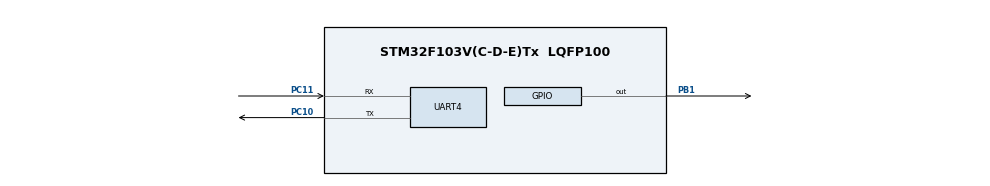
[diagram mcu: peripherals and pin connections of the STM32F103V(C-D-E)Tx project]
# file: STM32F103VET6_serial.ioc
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Mcu.Family=STM32F1
Mcu.Name=STM32F103V(C-D-E)Tx
Mcu.Package=LQFP100
NVIC.PriorityGroup=NVIC_PRIORITYGROUP_4
PB1.Signal=GPIO_Output
PC10.Mode=Asynchronous
PC10.Signal=UART4_TX
PC11.Mode=Asynchronous
PC11.Signal=UART4_RX
ProjectManager.HeapSize=0x200
ProjectManager.StackSize=0x400
ProjectManager.TargetToolchain=Makefile
RCC.APB1Freq_Value=8000000
RCC.APB2Freq_Value=8000000
UART4.VirtualMode=Asynchronous
VP_SYS_VS_ND.Mode=No_Debug
board=custom

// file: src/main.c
/* USER CODE BEGIN Header */
/**
******************************************************************************
* @file           : main.c
* @brief          : Main program body
******************************************************************************
* @attention
*
* <h2><center>&copy; Copyright (c) 2019 STMicroelectronics.
* All rights reserved.</center></h2>
*
* This software component is licensed by ST under BSD 3-Clause license,
* the "License"; You may not use this file except in compliance with the
* License. You may obtain a copy of the License at:
*                        opensource.org/licenses/BSD-3-Clause
*
******************************************************************************
*/
/* USER CODE END Header */

#include "main.h"
#include "uart.h"

UART_HandleTypeDef huart4;
uint8_t gSystemInitialized = 0;
uint8_t led = 0;

void SystemClock_Config(void);
static void MX_GPIO_Init(void);
static void MX_UART4_Init(void);

/* USER CODE BEGIN 0 */
void main_tick_1ms()   {
}
void main_tick_5ms()   {}
void main_tick_10ms()  {}
void main_tick_50ms()  {
    led = 1 - led;
    HAL_GPIO_WritePin(GPIOB, GPIO_PIN_1,led);
}
void main_tick_100ms() {}
void main_tick_500ms() {}
void main_tick_1s()    {
    /* while (!(UART4->SR & USART_SR_TXE)); */
    /* UART4->DR = 'a'; */
}
/* USER CODE END 0 */

int main(void)
{

    /* MCU Configuration--------------------------------------------------------*/

    /* Reset of all peripherals, Initializes the Flash interface and the Systick. */
    HAL_Init();

    /* Configure the system clock */
    SystemClock_Config();

    /* Initialize all configured peripherals */
    MX_GPIO_Init();
    MX_UART4_Init();
    /* USER CODE BEGIN 2 */
    gSystemInitialized=1;
    /* USER CODE END 2 */

    /* Infinite loop */
    while (1)
    {

    }
}

void SystemClock_Config(void)
{
    RCC_OscInitTypeDef RCC_OscInitStruct = {0};
    RCC_ClkInitTypeDef RCC_ClkInitStruct = {0};

    /** Initializes the CPU, AHB and APB busses clocks
     */
    RCC_OscInitStruct.OscillatorType = RCC_OSCILLATORTYPE_HSI;
    RCC_OscInitStruct.HSIState = RCC_HSI_ON;
    RCC_OscInitStruct.HSICalibrationValue = RCC_HSICALIBRATION_DEFAULT;
    RCC_OscInitStruct.PLL.PLLState = RCC_PLL_NONE;
    if (HAL_RCC_OscConfig(&RCC_OscInitStruct) != HAL_OK)
    {
        Error_Handler();
    }
    /** Initializes the CPU, AHB and APB busses clocks
     */
    RCC_ClkInitStruct.ClockType = RCC_CLOCKTYPE_HCLK|RCC_CLOCKTYPE_SYSCLK
        |RCC_CLOCKTYPE_PCLK1|RCC_CLOCKTYPE_PCLK2;
    RCC_ClkInitStruct.SYSCLKSource = RCC_SYSCLKSOURCE_HSI;
    RCC_ClkInitStruct.AHBCLKDivider = RCC_SYSCLK_DIV1;
    RCC_ClkInitStruct.APB1CLKDivider = RCC_HCLK_DIV1;
    RCC_ClkInitStruct.APB2CLKDivider = RCC_HCLK_DIV1;

    if (HAL_RCC_ClockConfig(&RCC_ClkInitStruct, FLASH_LATENCY_0) != HAL_OK)
    {
        Error_Handler();
    }
}

static void MX_UART4_Init(void)
{
    IRQn_Type irq;

    huart4.Instance = UART4; // PC10: TX, PC11: RX
    huart4.Init.BaudRate = 115200;
    huart4.Init.WordLength = UART_WORDLENGTH_8B;
    huart4.Init.StopBits = UART_STOPBITS_1;
    huart4.Init.Parity = UART_PARITY_NONE;
    huart4.Init.Mode = UART_MODE_TX_RX;
    huart4.Init.HwFlowCtl = UART_HWCONTROL_NONE;
    huart4.Init.OverSampling = UART_OVERSAMPLING_16;
    if (HAL_UART_Init(&huart4) != HAL_OK)
    {
        Error_Handler();
    }
    /* USER CODE BEGIN UART4_Init 2 */
    UART4->CR1 |= USART_CR1_TCIE;  // clear interrupt flag
    UART4->CR1 |=USART_CR1_RE | USART_CR1_TE;
    NVIC_SetPriority(irq, 0x00); // highest priority
    NVIC_EnableIRQ(irq);
    /* USER CODE END UART4_Init 2 */

}

static void MX_GPIO_Init(void)
{
    GPIO_InitTypeDef GPIO_InitStruct = {0};

    /* GPIO Ports Clock Enable */
    __HAL_RCC_GPIOB_CLK_ENABLE();
    __HAL_RCC_GPIOC_CLK_ENABLE();

    /*Configure GPIO pin Output Level */
    HAL_GPIO_WritePin(GPIOB, GPIO_PIN_1, GPIO_PIN_RESET);

    /*Configure GPIO pin : PB1 */
    GPIO_InitStruct.Pin = GPIO_PIN_1;
    GPIO_InitStruct.Mode = GPIO_MODE_OUTPUT_PP;
    GPIO_InitStruct.Pull = GPIO_NOPULL;
    GPIO_InitStruct.Speed = GPIO_SPEED_FREQ_LOW;
    HAL_GPIO_Init(GPIOB, &GPIO_InitStruct);

}

void Error_Handler(void)
{
}

/************************ (C) COPYRIGHT STMicroelectronics *****END OF FILE****/
